# RL6678_IP_SVD register map
Vendor: Realtek
Registers are 32-bit, read-write, reset 0x0 unless marked. A register's access mark holds for its fields unless they carry their own. Offsets are from the block's base; [hi:lo] are bit positions; {n}, {i} and the like mark numbered series; 'fields as' and 'values as' point back to an identical list.

## DDRPHY_REG (part 2 of 2)
Base 0x41011000
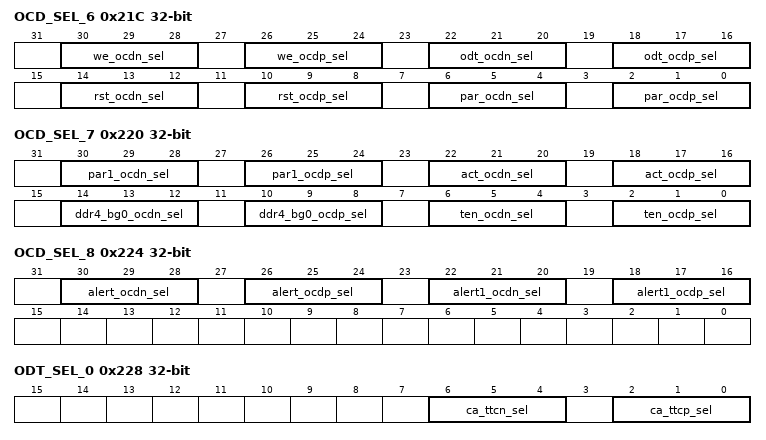
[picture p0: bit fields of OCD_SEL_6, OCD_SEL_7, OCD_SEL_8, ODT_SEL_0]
0x21C OCD_SEL_6
  [30:28] we_ocdn_sel — N-OCD selection for WEN 000: ocdn_set_0 ... 111: ocdn_set_7
  [26:24] we_ocdp_sel — P-OCD selection for WEN 000: ocdp_set_0 ... 111: ocdp_set_7
  [22:20] odt_ocdn_sel — N-OCD selection for ODT 000: ocdn_set_0 ... 111: ocdn_set_7
  [18:16] odt_ocdp_sel — P-OCD selection for ODT 000: ocdp_set_0 ... 111: ocdp_set_7
  [14:12] rst_ocdn_sel — N-OCD selection for RSTN 000: ocdn_set_0 ... 111: ocdn_set_7
  [10:8] rst_ocdp_sel — P-OCD selection for RSTN 000: ocdp_set_0 ... 111: ocdp_set_7
  [6:4] par_ocdn_sel — N-OCD selection for PAR 000: ocdn_set_0 ... 111: ocdn_set_7
  [2:0] par_ocdp_sel — P-OCD selection for PAR 000: ocdp_set_0 ... 111: ocdp_set_7
0x220 OCD_SEL_7
  [30:28] par1_ocdn_sel — N-OCD selection for PAR_1 000: ocdn_set_0 ... 111: ocdn_set_7
  [26:24] par1_ocdp_sel — P-OCD selection for PAR_1 000: ocdp_set_0 ... 111: ocdp_set_7
  [22:20] act_ocdn_sel — N-OCD selection for ACTN 000: ocdn_set_0 ... 111: ocdn_set_7
  [18:16] act_ocdp_sel — P-OCD selection for ACTN 000: ocdp_set_0 ... 111: ocdp_set_7
  [14:12] ddr4_bg0_ocdn_sel — N-OCD selection for DDR4_BG0 000: ocdn_set_0 ... 111: ocdn_set_7
  [10:8] ddr4_bg0_ocdp_sel — P-OCD selection for DDR4_BG0 000: ocdp_set_0 ... 111: ocdp_set_7
  [6:4] ten_ocdn_sel — N-OCD selection for DDR4_TEN 000: ocdn_set_0 ... 111: ocdn_set_7
  [2:0] ten_ocdp_sel — P-OCD selection for DDR4_TEN 000: ocdp_set_0 ... 111: ocdp_set_7
0x224 OCD_SEL_8
  [30:28] alert_ocdn_sel — N-OCD selection for ALERT 000: ocdn_set_0 ... 111: ocdn_set_7
  [26:24] alert_ocdp_sel — P-OCD selection for ALERT 000: ocdp_set_0 ... 111: ocdp_set_7
  [22:20] alert1_ocdn_sel — N-OCD selection for ALERT_1 000: ocdn_set_0 ... 111: ocdn_set_7
  [18:16] alert1_ocdp_sel — P-OCD selection for ALERT_1 000: ocdp_set_0 ... 111: ocdp_set_7
0x228 ODT_SEL_0
  [6:4] ca_ttcn_sel — TTCN selection for all address/command pad, except CKE and CSN 000: odt_ttcn_set_0 ... 111: odt_ttcn_set_7
  [2:0] ca_ttcp_sel — TTCP selection for all address/command pad, except CKE and CSN 000: odt_ttcp_set_0 ... 111: odt_ttcp_set_7
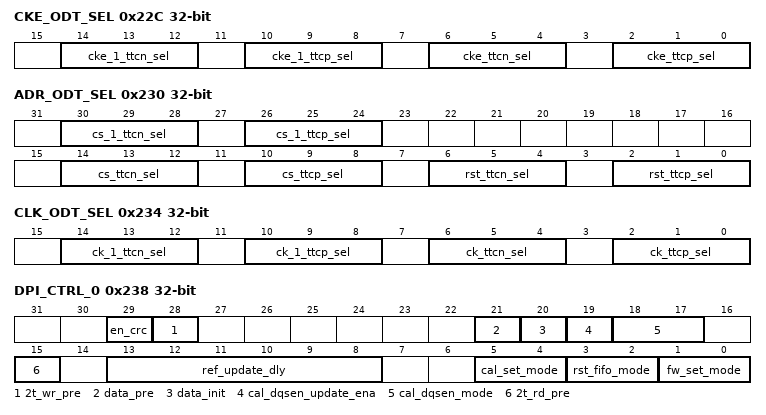
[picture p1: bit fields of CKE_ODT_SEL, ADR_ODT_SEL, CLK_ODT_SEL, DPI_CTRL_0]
0x22C CKE_ODT_SEL
  [14:12] cke_1_ttcn_sel — TTCN selection for CKE_1 (no use) 000: odt_ttcn_set_0 ... 111: odt_ttcn_set_7
  [10:8] cke_1_ttcp_sel — TTCP selection for CKE_1 (no use) 000: odt_ttcp_set_0 ... 111: odt_ttcp_set_7
  [6:4] cke_ttcn_sel — TTCN selection for CKE 000: odt_ttcn_set_0 ... 111: odt_ttcn_set_7
  [2:0] cke_ttcp_sel — TTCP selection for CKE 000: odt_ttcp_set_0 ... 111: odt_ttcp_set_7
0x230 ADR_ODT_SEL
  [30:28] cs_1_ttcn_sel — TTCN selection for CS_1 000: odt_ttcn_set_0 ... 111: odt_ttcn_set_7
  [26:24] cs_1_ttcp_sel — TTCP selection for CS_1 000: odt_ttcp_set_0 ... 111: odt_ttcp_set_7
  [14:12] cs_ttcn_sel — TTCN selection for CS 000: odt_ttcn_set_0 ... 111: odt_ttcn_set_7
  [10:8] cs_ttcp_sel — TTCP selection for CS 000: odt_ttcp_set_0 ... 111: odt_ttcp_set_7
  [6:4] rst_ttcn_sel — TTCN selection for RSTN 000: odt_ttcn_set_0 ... 111: odt_ttcn_set_7
  [2:0] rst_ttcp_sel — TTCP selection for RSTN 000: odt_ttcp_set_0 ... 111: odt_ttcp_set_7
0x234 CLK_ODT_SEL
  [14:12] ck_1_ttcn_sel — TTCN selection for CLK_1 000: odt_ttcn_set_0 ... 111: odt_ttcn_set_7
  [10:8] ck_1_ttcp_sel — TTCP selection for CLK_1 000: odt_ttcp_set_0 ... 111: odt_ttcp_set_7
  [6:4] ck_ttcn_sel — TTCN selection for CLK 000: odt_ttcn_set_0 ... 111: odt_ttcn_set_7
  [2:0] ck_ttcp_sel — TTCP selection for CLK 000: odt_ttcp_set_0 ... 111: odt_ttcp_set_7
0x238 DPI_CTRL_0
  [29] en_crc — [1] CRC enable (post one T more) for DDR4 only [0] no CRC
  [28] 2t_wr_pre — [1] 2T preamble for DDR4 only(Write) [0] 1T preamble
  [21] data_pre — 1: Enable Tx DQ preamble, enable this function will add 2T write delay in 2to1 mode, or 1T write delay in 1to1 mode
  [20] data_init — Set the Tx initial value of DQ/DM
  [19] cal_dqsen_update_ena — Enable HW auto-update tm_dqsen_ftun calibration value
  [18:17] cal_dqsen_mode — tm_dqs_en calibration set mode [00] during no read operation [01] during refresh [10] [11] disable auto calibration
  [15] 2t_rd_pre — [1] 2T preamble for DDR4 only (READ) [0] 1T preamble
  [13:8] ref_update_dly — Update delay chain setting after receiving refresh command
  [5:4] cal_set_mode — 3-point calibration set mode [00] during no read operation [01] during refresh [10] immediately [11] disable auto calibration
  [3:2] rst_fifo_mode — Reset read FIFO pointer mode [00] during no read operation [01] during refresh [10] disable reset FIFO pointer [11] force reset FIFO pointer
  [1:0] fw_set_mode — FW set delay chain of data slice mode [00] READ:during no read; WRITE: during refresh [01] during refresh [10] immediately [11] reserved
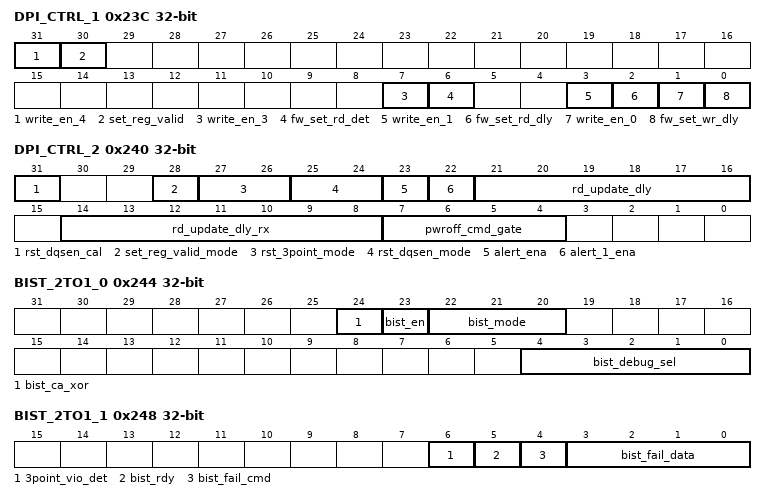
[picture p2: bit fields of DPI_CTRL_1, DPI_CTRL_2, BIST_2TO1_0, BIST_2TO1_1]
0x23C DPI_CTRL_1 access per field
  [31] write_en_4 wo — Enable of the following row
  [30] set_reg_valid rw — Set dll/rw register flow is as 1st: set_reg_valid = 0 2nd: ser any other dll/rw register 3rd : set_reg_valid = 1
  [7] write_en_3 wo — Enable of the following row
  [6] fw_set_rd_det wo — FW set read delay chain of valid window detection (one cycle pulse, HW auto clear)
  [3] write_en_1 wo — Enable of the following row
  [2] fw_set_rd_dly wo — FW set read delay chain TE and Delta of data slice (one cycle pulse, HW auto clear)
  [1] write_en_0 wo — Enable of the following row
  [0] fw_set_wr_dly rw — FW set write delay chain of data slice (one cycle pulse, HW auto clear)
0x240 DPI_CTRL_2
  [31] rst_dqsen_cal — 1'b0: disable reset fw_tm_dqs_en_ftun when reset dqsen_gen 1'b1: enable reset fw_tm_dqs_en_ftun when reset dqsen_gen
  [28] set_reg_valid_mode — [0] trigger set_reg_valid manually [1] trigger set_reg_valid automatically
  [27:26] rst_3point_mode — Reset dqsen_gen mode [00] disable reset 3 point [01] force reset 3 point [10] reserved [11] during refresh
  [25:24] rst_dqsen_mode — Reset dqsen_gen mode [00] disable reset RX dqsen_gen [01] force reset RX dqsen_gen [10] reserved [11] during refresh
  [23] alert_ena — DFI alert output enable
  [22] alert_1_ena — DFI alert_1 output enable
  [21:16] rd_update_dly — Update delay chain setting after read data enable Cmd domain 2to1 mode : > 1/2 rd_update_dly_rx +N 1to1 mode : > rd_update_dly_rx +N
  [14:8] rd_update_dly_rx — Update delay chain setting after read data enable Rx domain
  [7:4] pwroff_cmd_gate — 1: Let the following signals always be 1. [0]: let dfi_wr_cmd_01 always be 1. [1]: let dfi_wr_cmd_23 always be 1. [2]: let dfi_rd_cmd_01 always be 1. [3]: let dfi_rd_cmd_23 always be 1.
0x244 BIST_2TO1_0
  [24] bist_ca_xor — XOR dfi_wrdata_p* with dfi C/A signals for controller loopback test dfi_wrdata_xor_p0[63:0] = dfi_wrdata_p0[63:0] ^ { 8'h0, dfi_ten_in_p0, dfi_parity_in_p0, dfi_act_n_p0, dfi_bg0_p0, ^dfi_odt_p0[1:0], ^dfi_cke_1_p0[1:0], ^dfi_cke_p0[1:0], ^dfi_cs_n_1_p0[1:0], ^dfi_cs_n_p0[1:0], ^dfi_we_n_p0[1:0], ^dfi_ras_n_p0[1:0], ^dfi_cas_n_p0[1:0], dfi_bank_p0[5:0], dfi_address_ext_p0[3:0], dfi_address_p0[33:0]}; dfi_wrdata_xor_p1[63:0] = dfi_wrdata_p1[63:0] ^ { 8'h0, dfi_ten_in_p1, dfi_parity_in_p1, dfi_act_n_p1, dfi_bg0_p1, ^dfi_odt_p1[1:0], ^dfi_cke_1_p1[1:0], ^dfi_cke_p1[1:0], ^dfi_cs_n_1_p1[1:0], ^dfi_cs_n_p1[1:0], ^dfi_we_n_p1[1:0], ^dfi_ras_n_p1[1:0], ^dfi_cas_n_p1[1:0], dfi_bank_p1[5:0], dfi_address_ext_p1[3:0], dfi_address_p1[33:0]};
  [23] bist_en — 1Enable bist circuit in PHY. 0Disable bist circuit & reset all flag of bist.
  [22:20] bist_mode — Bist mode: 000 PRBS11. 001 PRBS13. 010 PRBS31.
  [4:0] bist_debug_sel — debug selection
0x248 BIST_2TO1_1 ro
  [6] 3point_vio_det — 1 means Rx 3-point lead/lag has happened. To clear this flag, set VALID_WIN_DET_PFIFO_*, VALID_WIN_DET_NFIFO_* to all 0.
  [5] bist_rdy — When bist is finished, then bist_rdy = 1 until bist_en = 0.
  [4] bist_fail_cmd — Reserved.
  [3:0] bist_fail_data — Fail flag for DDR PHY's data slice. If bist fail, then fail flag = 1 until bist_en = 0.
0x24C BIST_PT
  [31:0] bist_pattern — BIST initial pattern
0x250 BIST_DEBUG ro
  [31:0] bist_debug — BIST debug out
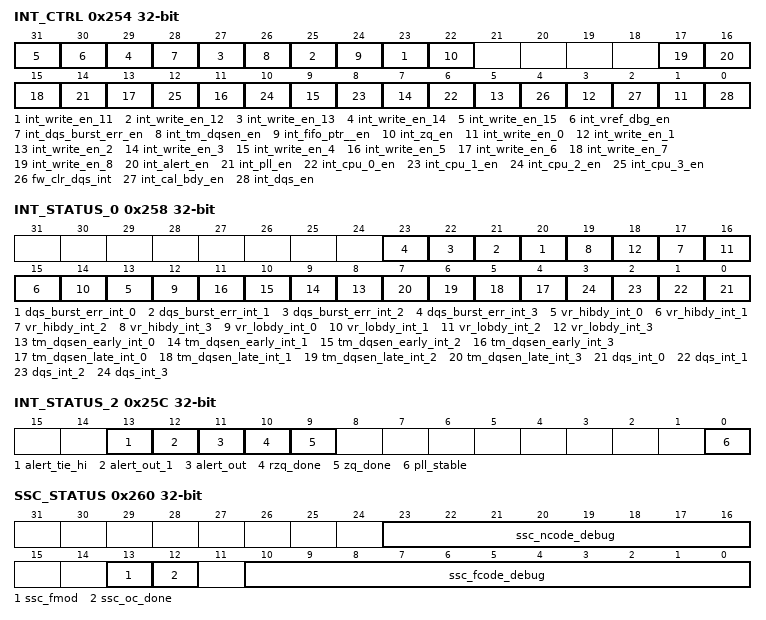
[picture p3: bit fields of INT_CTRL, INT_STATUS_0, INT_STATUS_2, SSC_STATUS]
0x254 INT_CTRL access per field
  [2n+1] int_write_en_{n} wo (n=11..15) — Enable of the following row
  [30] int_vref_dbg_en wo — Vref debug INT enable
  [28] int_dqs_burst_err_en rw — Rx DQS burst length error INT enable
  [26] int_tm_dqsen_en rw — tm_dqs_en calibration INT enable
  [24] int_fifo_ptr__en rw — fifo_prt_int enable
  [22] int_zq_en rw — Enable ZQ / RZQ done interrupt
  [2n+1] int_write_en_{n} wo (n=0..8) — Enable of the following row
  [16] int_alert_en rw — Enable alert_out interrupt
  [14] int_pll_en rw — Enable PLL stable interrupt
  [2n+6] int_cpu_{n}_en rw (n=0..3) — To CPU {n} interrupt enable
  [4] fw_clr_dqs_int wo — FW clear dqs_int & tm_dqsen_late_int & tm_dqsen_early_int (one cycle pulse, HW auto clear)
  [2] int_cal_bdy_en rw — cal_bdy_int enable
  [0] int_dqs_en rw — dqs_int enable
0x258 INT_STATUS_0
  [n+20] dqs_burst_err_int_{n} (n=0..3) — dqs_burst_err_int of data slice{n}
  [2n+13] vr_hibdy_int_{n} (n=0..3) — Byte-{n} Vref hit high boundary
  [2n+12] vr_lobdy_int_{n} (n=0..3) — Byte-{n} Vref hit low boundary
  [n+8] tm_dqsen_early_int_{n} (n=0..3) — tm_dqs_en calibration early int of slice {n}
  [n+4] tm_dqsen_late_int_{n} (n=0..3) — tm_dqs_en calibration late int of slice {n}
  [n] dqs_int_{n} (n=0..3) — dqs_int of data slice{n}
0x25C INT_STATUS_2
  [13] alert_tie_hi — 1'b1 means alert pad was tied to high
  [12] alert_out_1 — 1'b1 means alert_out_1 goes low
  [11] alert_out — 1'b1 means alert_out_0 goes low
  [10] rzq_done — RZQ calibration done
  [9] zq_done — ZQ calibration done
  [0] pll_stable
0x260 SSC_STATUS ro
  [23:16] ssc_ncode_debug — Ncode of PLL using now, for debug
  [13] ssc_fmod — 1 : under-clock 0 : over-clock
  [12] ssc_oc_done — Indicate over-clock or under-clock done
  [10:0] ssc_fcode_debug — Fcode of PLL using now, for debug
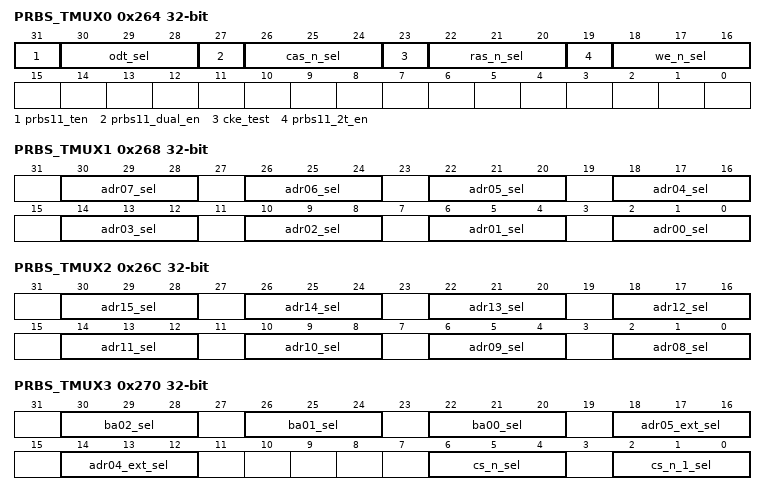
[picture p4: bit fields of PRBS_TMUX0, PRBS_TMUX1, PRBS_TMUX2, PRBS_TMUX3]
0x264 PRBS_TMUX0
  [31] prbs11_ten — PRBS11 test enable
  [30:28] odt_sel — 000: force 0 001: force 1 010: PRBS11 011: PRBS11 invert 100: PRBS11 delay one clock cycle 101: from test_pattern register 110: test_pattern invert
  [27] prbs11_dual_en — PRBS11 Dual edge enable
  [26:24] cas_n_sel — 000: force 0 001: force 1 010: PRBS11 011: PRBS11 invert 100: PRBS11 delay one clock cycle 101: from test_pattern register 110: test_pattern invert
  [23] cke_test — 1: force 1 ,0: force 0
  [22:20] ras_n_sel — 000: force 0 001: force 1 010: PRBS11 011: PRBS11 invert 100: PRBS11 delay one clock cycle 101: from test_pattern register 110: test_pattern invert
  [19] prbs11_2t_en — 1: CMD 2T ,0: CMD 1T
  [18:16] we_n_sel — 000: force 0 001: force 1 010: PRBS11 011: PRBS11 invert 100: PRBS11 delay one clock cycle 101: from test_pattern register 110: test_pattern invert
0x268 PRBS_TMUX1
  [4n+2:4n] adr{n:02}_sel (n=0..7) — 000: force 0 001: force 1 010: PRBS11 011: PRBS11 invert 100: PRBS11 delay one clock cycle 101: from test_pattern register 110: test_pattern invert
0x26C PRBS_TMUX2
  [4n-30:4n-32] adr{n:02}_sel (n=8..15) — 000: force 0 001: force 1 010: PRBS11 011: PRBS11 invert 100: PRBS11 delay one clock cycle 101: from test_pattern register 110: test_pattern invert
0x270 PRBS_TMUX3
  [30:28] ba02_sel — 000: force 0 001: force 1 010: PRBS11 011: PRBS11 invert 100: PRBS11 delay one clock cycle 101: from test_pattern register 110: test_pattern invert
  [26:24] ba01_sel — 000: force 0 001: force 1 010: PRBS11 011: PRBS11 invert 100: PRBS11 delay one clock cycle 101: from test_pattern register 110: test_pattern invert
  [22:20] ba00_sel — 000: force 0 001: force 1 010: PRBS11 011: PRBS11 invert 100: PRBS11 delay one clock cycle 101: from test_pattern register 110: test_pattern invert
  [18:16] adr05_ext_sel — 000: force 0 001: force 1 010: PRBS11 011: PRBS11 invert 100: PRBS11 delay one clock cycle 101: from test_pattern register 110: test_pattern invert
  [14:12] adr04_ext_sel — 000: force 0 001: force 1 010: PRBS11 011: PRBS11 invert 100: PRBS11 delay one clock cycle 101: from test_pattern register 110: test_pattern invert
  [6:4] cs_n_sel — 000: force 0 001: force 1 010: PRBS11 011: PRBS11 invert 100: PRBS11 delay one clock cycle 101: from test_pattern register 110: test_pattern invert
  [2:0] cs_n_1_sel — 000: force 0 001: force 1 010: PRBS11 011: PRBS11 invert 100: PRBS11 delay one clock cycle 101: from test_pattern register 110: test_pattern invert
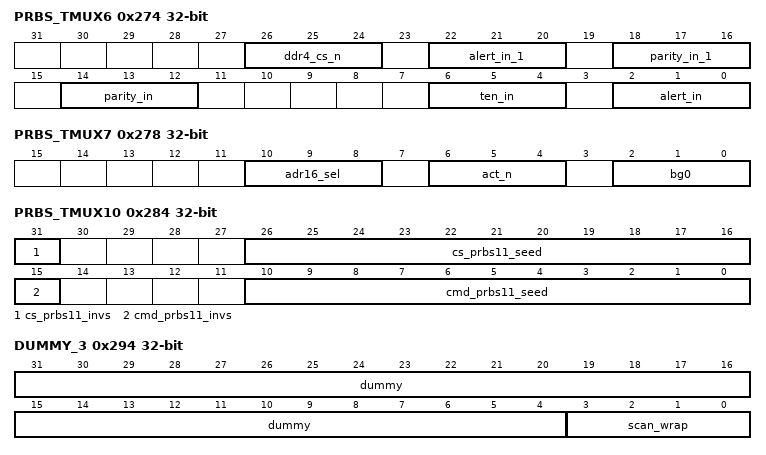
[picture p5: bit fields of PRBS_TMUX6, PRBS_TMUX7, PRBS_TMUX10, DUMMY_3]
0x274 PRBS_TMUX6
  [26:24] ddr4_cs_n — 000: force 0 001: force 1 010: PRBS11 011: PRBS11 invert 100: PRBS11 delay one clock cycle 101: from test_pattern register 110: test_pattern invert
  [22:20] alert_in_1 — 000: force 0 001: force 1 010: PRBS11 011: PRBS11 invert 100: PRBS11 delay one clock cycle 101: from test_pattern register 110: test_pattern invert
  [18:16] parity_in_1 — 000: force 0 001: force 1 010: PRBS11 011: PRBS11 invert 100: PRBS11 delay one clock cycle 101: from test_pattern register 110: test_pattern invert
  [14:12] parity_in — 000: force 0 001: force 1 010: PRBS11 011: PRBS11 invert 100: PRBS11 delay one clock cycle 101: from test_pattern register 110: test_pattern invert
  [6:4] ten_in — 000: force 0 001: force 1 010: PRBS11 011: PRBS11 invert 100: PRBS11 delay one clock cycle 101: from test_pattern register 110: test_pattern invert
  [2:0] alert_in — 000: force 0 001: force 1 010: PRBS11 011: PRBS11 invert 100: PRBS11 delay one clock cycle 101: from test_pattern register 110: test_pattern invert
0x278 PRBS_TMUX7
  [10:8] adr16_sel — 000: force 0 001: force 1 010: PRBS11 011: PRBS11 invert 100: PRBS11 delay one clock cycle 101: from test_pattern register 110: test_pattern invert
  [6:4] act_n — 000: force 0 001: force 1 010: PRBS11 011: PRBS11 invert 100: PRBS11 delay one clock cycle 101: from test_pattern register 110: test_pattern invert
  [2:0] bg0 — 000: force 0 001: force 1 010: PRBS11 011: PRBS11 invert 100: PRBS11 delay one clock cycle 101: from test_pattern register 110: test_pattern invert
0x27C PRBS_TMUX8
  [31:0] test_pattern — 32-bit test pattern for prbs11 or ten: [16: 0] : Addr[16:0] [18:17] : Ext_Addr[5:4] [21:19] : BA [22] : CS_n [23] : CS_n_1 [24] : RESET_n [25] : CKE [26] : ODT [27] : WE_n [28] : CAS_n [29] : RAS_n [30] : CKE_1
0x280 PRBS_TMUX9
  [31:0] test4_pattern — 32-bit test pattern for prbs11 or ten: [31:8] : reserved [07] : DDR4_CS_n [06] : ACT_n [05] : DDR4_CKE [04] : DDR4_BG0 [03] : PARITY_in [02] : PARITY_in_1 [01] : ALERT_in [00] : ALERT_in_1
0x284 PRBS_TMUX10
  [31] cs_prbs11_invs — inverted PRBS11 for CS
  [26:16] cs_prbs11_seed — PRBS11 seed for CS
  [15] cmd_prbs11_invs — inverted PRBS11 for CMD/ADR
  [10:0] cmd_prbs11_seed — PRBS11 seed for CMD / ADR
{0x288+4i} DUMMY_{i} (i=0..2)
  [31:0] dummy
0x294 DUMMY_3
  [31:4] dummy
  [3:0] scan_wrap — dummy register for scan test coverage
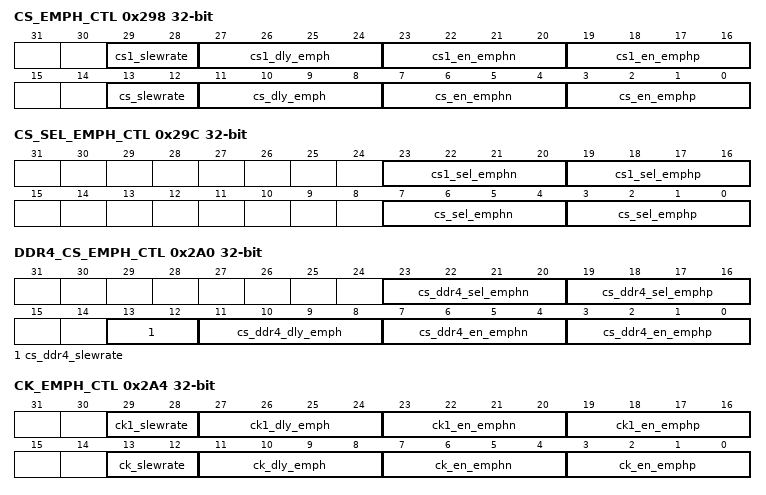
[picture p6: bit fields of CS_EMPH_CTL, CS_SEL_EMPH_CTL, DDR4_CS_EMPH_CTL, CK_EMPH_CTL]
0x298 CS_EMPH_CTL
  [29:28] cs1_slewrate — CS1_n slew rate control pin
  [27:24] cs1_dly_emph — CS1_n Delay tap control pin (no use)
  [23:20] cs1_en_emphn — CS1_n Emphasis control pin (no use)
  [19:16] cs1_en_emphp — CS1_n Emphasis control pin (no use)
  [13:12] cs_slewrate — CS_n slew rate control pin
  [11:8] cs_dly_emph — CS_n Delay tap control pin (no use)
  [7:4] cs_en_emphn — CS_n Emphasis control pin (no use)
  [3:0] cs_en_emphp — CS_n Emphasis control pin (no use)
0x29C CS_SEL_EMPH_CTL
  [23:20] cs1_sel_emphn — CS1_n SEL Emphasis control pin
  [19:16] cs1_sel_emphp — CS1_n SEL Emphasis control pin
  [7:4] cs_sel_emphn — CS_n SEL Emphasis control pin
  [3:0] cs_sel_emphp — CS_n SEL Emphasis control pin
0x2A0 DDR4_CS_EMPH_CTL
  [23:20] cs_ddr4_sel_emphn — CS_n SEL Emphasis control pin
  [19:16] cs_ddr4_sel_emphp — CS_n SEL Emphasis control pin
  [13:12] cs_ddr4_slewrate — DDR4 CS_n slew rate control pin
  [11:8] cs_ddr4_dly_emph — DDR4 CS_n Delay tap control pin (no use)
  [7:4] cs_ddr4_en_emphn — DDR4 CS_n Emphasis control pin (no use)
  [3:0] cs_ddr4_en_emphp — DDR4 CS_n Emphasis control pin (no use)
0x2A4 CK_EMPH_CTL
  [29:28] ck1_slewrate — CK1 slew rate control pin
  [27:24] ck1_dly_emph — CK1 Delay tap control pin (no use)
  [23:20] ck1_en_emphn — CK1 Emphasis control pin (no use)
  [19:16] ck1_en_emphp — CK1 Emphasis control pin (no use)
  [13:12] ck_slewrate — CK slew rate control pin
  [11:8] ck_dly_emph — CK Delay tap control pin (no use)
  [7:4] ck_en_emphn — CK Emphasis control pin (no use)
  [3:0] ck_en_emphp — CK Emphasis control pin (no use)
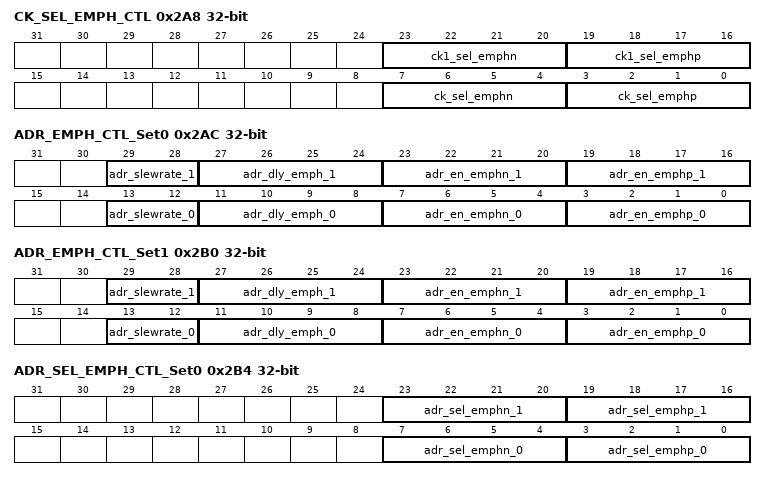
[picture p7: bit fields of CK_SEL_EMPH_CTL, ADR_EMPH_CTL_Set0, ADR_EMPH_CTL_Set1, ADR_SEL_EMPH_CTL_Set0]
0x2A8 CK_SEL_EMPH_CTL
  [23:20] ck1_sel_emphn — CK1 SEL Emphasis control pin
  [19:16] ck1_sel_emphp — CK1 SEL Emphasis control pin
  [7:4] ck_sel_emphn — CK sel Emphasis control pin
  [3:0] ck_sel_emphp — CK sel Emphasis control pin
0x2AC ADR_EMPH_CTL_Set0
  [29:28] adr_slewrate_1 — ADR/CMD slew rate control pin
  [27:24] adr_dly_emph_1 — ADR/CMD Delay tap control pin 1 (no use)
  [23:20] adr_en_emphn_1 — ADR/CMD Emphasis control pin 1 (no use)
  [19:16] adr_en_emphp_1 — ADR/CMD Emphasis control pin 1 (no use)
  [13:12] adr_slewrate_0 — ADR/CMD slew rate control pin 0
  [11:8] adr_dly_emph_0 — ADR/CMD Delay tap control pin 0 (no use)
  [7:4] adr_en_emphn_0 — ADR/CMD Emphasis control pin 0 (no use)
  [3:0] adr_en_emphp_0 — ADR/CMD Emphasis control pin 0 (no use)
0x2B0 ADR_EMPH_CTL_Set1
  fields as ADR_EMPH_CTL_Set0
0x2B4 ADR_SEL_EMPH_CTL_Set0
  [23:20] adr_sel_emphn_1 — ADR/CMD Emphasis control pin 1
  [19:16] adr_sel_emphp_1 — ADR/CMD Emphasis control pin 1
  [7:4] adr_sel_emphn_0 — ADR/CMD Emphasis control pin 0
  [3:0] adr_sel_emphp_0 — ADR/CMD Emphasis control pin 0
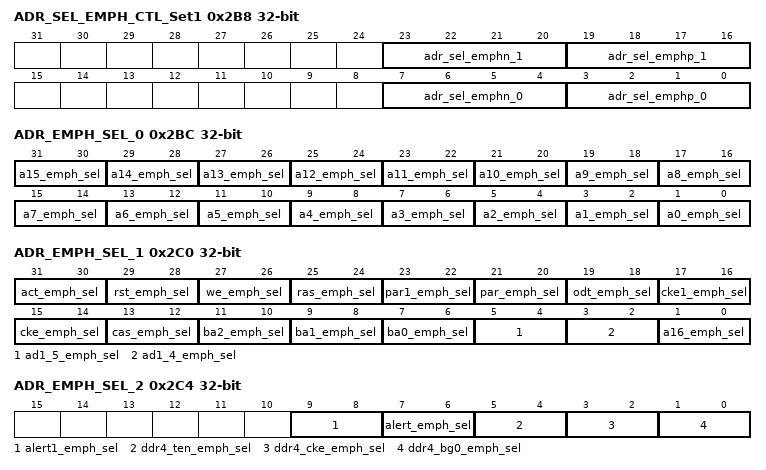
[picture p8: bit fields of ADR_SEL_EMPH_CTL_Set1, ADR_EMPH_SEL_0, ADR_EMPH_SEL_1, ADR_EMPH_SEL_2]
0x2B8 ADR_SEL_EMPH_CTL_Set1
  fields as ADR_SEL_EMPH_CTL_Set0
0x2BC ADR_EMPH_SEL_0
  [2n+1:2n] a{n}_emph_sel (n=0..15) — Tx emphasis control of PAD_DDR_A{n} 00: use ADR/CMD emphasis control set 0 01: use ADR/CMD emphasis control set 1 10: use ADR/CMD emphasis control set 2 11: use ADR/CMD emphasis control set 3
0x2C0 ADR_EMPH_SEL_1
  [31:30] act_emph_sel — Tx emphasis control of PAD_DDR_ACTN 00: use ADR/CMD emphasis control set 0 01: use ADR/CMD emphasis control set 1 10: use ADR/CMD emphasis control set 2 11: use ADR/CMD emphasis control set 3
  [29:28] rst_emph_sel — Tx emphasis control of PAD_DDR_RSTN 00: use ADR/CMD emphasis control set 0 01: use ADR/CMD emphasis control set 1 10: use ADR/CMD emphasis control set 2 11: use ADR/CMD emphasis control set 3
  [27:26] we_emph_sel — Tx emphasis control of PAD_DDR_WEN 00: use ADR/CMD emphasis control set 0 01: use ADR/CMD emphasis control set 1 10: use ADR/CMD emphasis control set 2 11: use ADR/CMD emphasis control set 3
  [25:24] ras_emph_sel — Tx emphasis control of PAD_DDR_RASN 00: use ADR/CMD emphasis control set 0 01: use ADR/CMD emphasis control set 1 10: use ADR/CMD emphasis control set 2 11: use ADR/CMD emphasis control set 3
  [23:22] par1_emph_sel — Tx emphasis control of PAD_DDR4_PAR_1 00: use ADR/CMD emphasis control set 0 01: use ADR/CMD emphasis control set 1 10: use ADR/CMD emphasis control set 2 11: use ADR/CMD emphasis control set 3
  [21:20] par_emph_sel — Tx emphasis control of PAD_DDR4_PAR 00: use ADR/CMD emphasis control set 0 01: use ADR/CMD emphasis control set 1 10: use ADR/CMD emphasis control set 2 11: use ADR/CMD emphasis control set 3
  [19:18] odt_emph_sel — Tx emphasis control of PAD_DDR_ODT 00: use ADR/CMD emphasis control set 0 01: use ADR/CMD emphasis control set 1 10: use ADR/CMD emphasis control set 2 11: use ADR/CMD emphasis control set 3
  [17:16] cke1_emph_sel — Tx emphasis control of PAD_DDR_CKE_1 00: use ADR/CMD emphasis control set 0 01: use ADR/CMD emphasis control set 1 10: use ADR/CMD emphasis control set 2 11: use ADR/CMD emphasis control set 3
  [15:14] cke_emph_sel — Tx emphasis control of PAD_DDR_CKE 00: use ADR/CMD emphasis control set 0 01: use ADR/CMD emphasis control set 1 10: use ADR/CMD emphasis control set 2 11: use ADR/CMD emphasis control set 3
  [13:12] cas_emph_sel — Tx emphasis control of PAD_DDR_CASN 00: use ADR/CMD emphasis control set 0 01: use ADR/CMD emphasis control set 1 10: use ADR/CMD emphasis control set 2 11: use ADR/CMD emphasis control set 3
  [11:10] ba2_emph_sel — Tx emphasis control of PAD_DDR_BA2 00: use ADR/CMD emphasis control set 0 01: use ADR/CMD emphasis control set 1 10: use ADR/CMD emphasis control set 2 11: use ADR/CMD emphasis control set 3
  [9:8] ba1_emph_sel — Tx emphasis control of PAD_DDR_BA1 00: use ADR/CMD emphasis control set 0 01: use ADR/CMD emphasis control set 1 10: use ADR/CMD emphasis control set 2 11: use ADR/CMD emphasis control set 3
  [7:6] ba0_emph_sel — Tx emphasis control of PAD_DDR_BA0 00: use ADR/CMD emphasis control set 0 01: use ADR/CMD emphasis control set 1 10: use ADR/CMD emphasis control set 2 11: use ADR/CMD emphasis control set 3
  [5:4] ad1_5_emph_sel — Tx emphasis control of PAD_DDR_AD1_5 00: use ADR/CMD emphasis control set 0 01: use ADR/CMD emphasis control set 1 10: use ADR/CMD emphasis control set 2 11: use ADR/CMD emphasis control set 3
  [3:2] ad1_4_emph_sel — Tx emphasis control of PAD_DDR_AD1_4 00: use ADR/CMD emphasis control set 0 01: use ADR/CMD emphasis control set 1 10: use ADR/CMD emphasis control set 2 11: use ADR/CMD emphasis control set 3
  [1:0] a16_emph_sel — Tx emphasis control of PAD_DDR_A16 00: use ADR/CMD emphasis control set 0 01: use ADR/CMD emphasis control set 1 10: use ADR/CMD emphasis control set 2 11: use ADR/CMD emphasis control set 3
0x2C4 ADR_EMPH_SEL_2
  [9:8] alert1_emph_sel — Tx emphasis control of PAD_DDR_ALERT_1 00: use ADR/CMD emphasis control set 0 01: use ADR/CMD emphasis control set 1 10: use ADR/CMD emphasis control set 2 11: use ADR/CMD emphasis control set 3
  [7:6] alert_emph_sel — Tx emphasis control of PAD_DDR_ALERT 00: use ADR/CMD emphasis control set 0 01: use ADR/CMD emphasis control set 1 10: use ADR/CMD emphasis control set 2 11: use ADR/CMD emphasis control set 3
  [5:4] ddr4_ten_emph_sel — Tx emphasis control of PAD_DDR4_TEN 00: use ADR/CMD emphasis control set 0 01: use ADR/CMD emphasis control set 1 10: use ADR/CMD emphasis control set 2 11: use ADR/CMD emphasis control set 3
  [3:2] ddr4_cke_emph_sel — Tx emphasis control of PAD_DDR4_CKE 00: use ADR/CMD emphasis control set 0 01: use ADR/CMD emphasis control set 1 10: use ADR/CMD emphasis control set 2 11: use ADR/CMD emphasis control set 3
  [1:0] ddr4_bg0_emph_sel — Tx emphasis control of PAD_DDR4_BG0 00: use ADR/CMD emphasis control set 0 01: use ADR/CMD emphasis control set 1 10: use ADR/CMD emphasis control set 2 11: use ADR/CMD emphasis control set 3
0x2C8 DBG_READ_0 ro
  [31:0] dqsen_dbg — Use dqsen_dbg_sel[1:0] to select dqsen_dbg_0, dqsen_dbg_1, dqsen_dbg_2, dqsen_dbg_3
0x2CC DBG_READ_1 ro
  [31:0] dpi_dbg_dll — Use dpi_dbg_dll_sel to select dpi_debug_dll[31:0] or dpi_debug_dll[63:32]
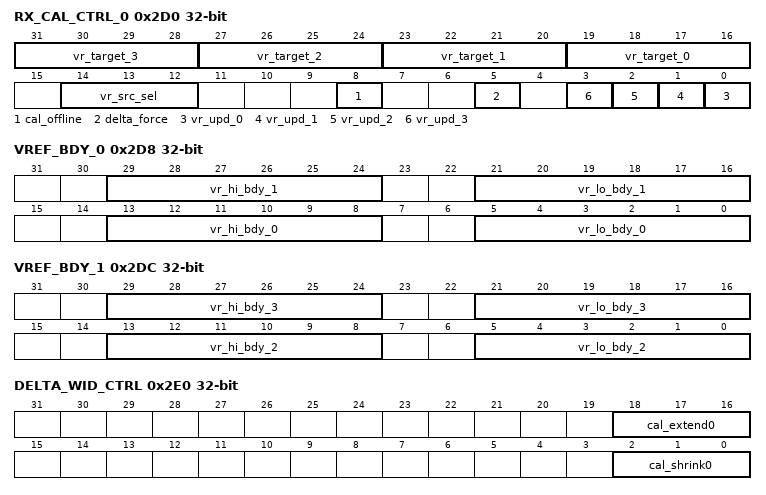
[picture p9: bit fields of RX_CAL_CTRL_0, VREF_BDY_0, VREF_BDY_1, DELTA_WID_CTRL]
0x2D0 RX_CAL_CTRL_0
  [4n+19:4n+16] vr_target_{n} (n=0..3) — Vref calibration process will stop if the minimum delta width is greater than or equal to this value. This is for byte-{n} Vref.
  [14:12] vr_src_sel — Select data source of Vref update criteria
  [8] cal_offline — 1: TE only move in one direction, and Delta only decrease. This mode should only be used in offline or fore-ground calibration to find the minimum working Rx delay taps.
  [5] delta_force — force delta value without double-buffer
  [n] vr_upd_{n} (n=0..3) — 1: vref_s_{n} can be applied to Vref pad by fw_set_rd_dly
0x2D4 RX_CAL_CTRL_1
  [5:0] vr_cnt_target — update Vref when target count is reached 0 : disable Vref calibration
0x2D8 VREF_BDY_0
  [29:24] vr_hi_bdy_1 — Vref1 high boundary for rw_blk_01
  [21:16] vr_lo_bdy_1 — Vref1 low boundary for rw_blk_01
  [13:8] vr_hi_bdy_0 — Vref0 high boundary for rw_blk_01
  [5:0] vr_lo_bdy_0 — Vref0 low boundary for rw_blk_01
0x2DC VREF_BDY_1
  [29:24] vr_hi_bdy_3 — Vref3 high boundary for rw_blk_23
  [21:16] vr_lo_bdy_3 — Vref3 low boundary for rw_blk_23
  [13:8] vr_hi_bdy_2 — Vref2 high boundary for rw_blk_23
  [5:0] vr_lo_bdy_2 — Vref2 low boundary for rw_blk_23
0x2E0 DELTA_WID_CTRL
  [18:16] cal_extend0 — extend width of delta when calibration result is extend[0] = 1 [2's complement format] (sign, 2.0) 000: 0 001: 1 010: 2 011: 3
  [2:0] cal_shrink0 — shrink width of delta when calibration result is shrink[0] = 1 [2's complement format] (sign, 2.0) 111: -1 110: -2 101: -3 100: -4
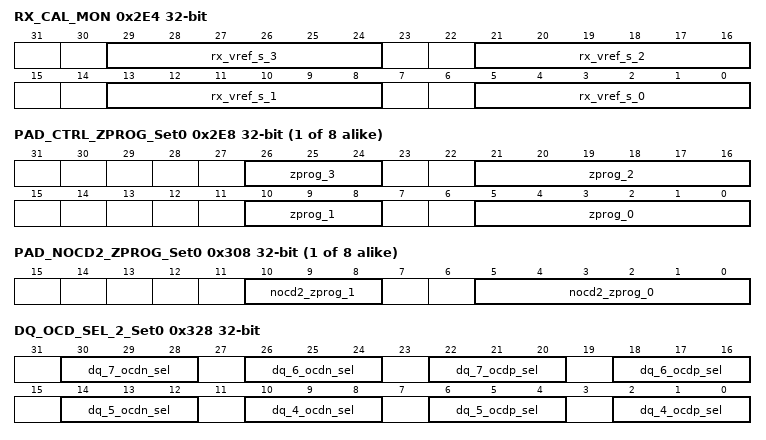
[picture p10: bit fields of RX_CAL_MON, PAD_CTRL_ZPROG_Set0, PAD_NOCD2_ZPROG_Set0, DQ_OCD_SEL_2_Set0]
0x2E4 RX_CAL_MON ro
  [8n+5:8n] rx_vref_s_{n} (n=0..3) — calibrated Vref value of byte-{n}
{0x2E8+4i} PAD_CTRL_ZPROG_Set{i} (i=0..7)
  [26:24] zprog_3 — NODT vpcal_sel
  [21:16] zprog_2 — NODT pad pocd value
  [10:8] zprog_1 — NOCD vpcal_sel
  [5:0] zprog_0 — NOCD pad pocd value
{0x308+4i} PAD_NOCD2_ZPROG_Set{i} (i=0..7)
  [10:8] nocd2_zprog_1 — NOCD2 vpcal_sel
  [5:0] nocd2_zprog_0 — NOCD2 pad pocd value
0x328 DQ_OCD_SEL_2_Set0
  [30:28] dq_7_ocdn_sel — Set 0: NT2 selection for slice3 DQ Set 1: EN_EMPHN selection for slice3 DQ 000: ocdn_set_0 ... 111: ocdn_set_7
  [26:24] dq_6_ocdn_sel — Set 0: NT2 selection for slice2 DQ Set 1: EN_EMPHN selection for slice2 DQ 000: ocdn_set_0 ... 111: ocdn_set_7
  [22:20] dq_7_ocdp_sel — Set 0: PT2 selection for slice3 DQ Set 1: EN_EMPHP selection for slice3 DQ 000: ocdp_set_0 ... 111: ocdp_set_7
  [18:16] dq_6_ocdp_sel — Set 0: PT2 selection for slice2 DQ Set 1: EN_EMPHP selection for slice2 DQ 000: ocdp_set_0 ... 111: ocdp_set_7
  [14:12] dq_5_ocdn_sel — Set 0: NT2 selection for slice1 DQ Set 1: EN_EMPHN selection for slice1 DQ 000: ocdn_set_0 ... 111: ocdn_set_7
  [10:8] dq_4_ocdn_sel — Set 0: NT2 selection for slice0 DQ Set 1: EN_EMPHN selection for slice0 DQ 000: ocdn_set_0 ... 111: ocdn_set_7
  [6:4] dq_5_ocdp_sel — Set 0: PT2 selection for slice1 DQ Set 1: EN_EMPHP selection for slice1 DQ 000: ocdp_set_0 ... 111: ocdp_set_7
  [2:0] dq_4_ocdp_sel — Set 0: PT2 selection for slice0 DQ Set 1: EN_EMPHP selection for slice0 DQ 000: ocdp_set_0 ... 111: ocdp_set_7
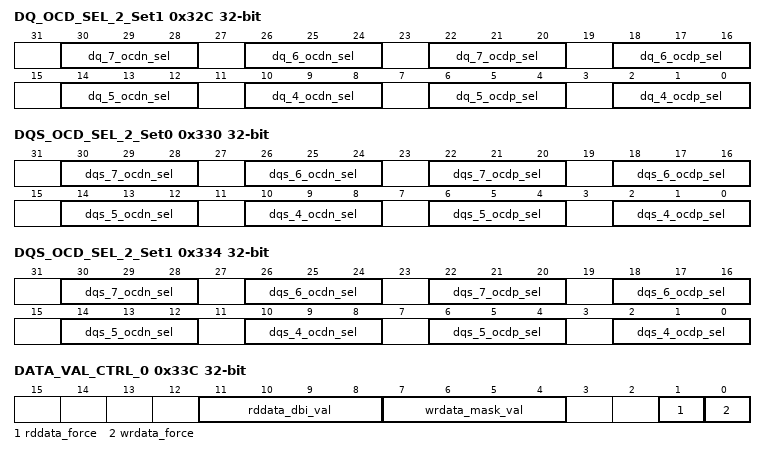
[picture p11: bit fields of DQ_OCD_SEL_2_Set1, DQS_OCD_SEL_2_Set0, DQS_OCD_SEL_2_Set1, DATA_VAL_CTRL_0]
0x32C DQ_OCD_SEL_2_Set1
  fields as DQ_OCD_SEL_2_Set0
0x330 DQS_OCD_SEL_2_Set0
  [30:28] dqs_7_ocdn_sel — Set 0: NT2 selection for DQS[3] Set 1: EN_EMPHN selection for DQS[3] 000: ocdn_set_0 ... 111: ocdn_set_7
  [26:24] dqs_6_ocdn_sel — Set 0: NT2 selection for DQS[2] Set 1: EN_EMPHN selection for DQS[2] 000: ocdn_set_0 ... 111: ocdn_set_7
  [22:20] dqs_7_ocdp_sel — Set 0: PT2 selection for DQS[3] Set 1: EN_EMPHP selection for DQS[3] 000: ocdp_set_0 ... 111: ocdp_set_7
  [18:16] dqs_6_ocdp_sel — Set 0: PT2 selection for DQS[2] Set 1: EN_EMPHP selection for DQS[2] 000: ocdp_set_0 ... 111: ocdp_set_7
  [14:12] dqs_5_ocdn_sel — Set 0: NT2 selection for DQS[1] Set 1: EN_EMPHN selection for DQS[1] 000: ocdn_set_0 ... 111: ocdn_set_7
  [10:8] dqs_4_ocdn_sel — Set 0: NT2 selection for DQS[0] Set 1: EN_EMPHN selection for DQS[0] 000: ocdn_set_0 ... 111: ocdn_set_7
  [6:4] dqs_5_ocdp_sel — Set 0: PT2 selection for DQS[1] Set 1: EN_EMPHP selection for DQS[1] 000: ocdp_set_0 ... 111: ocdp_set_7
  [2:0] dqs_4_ocdp_sel — Set 0: PT2 selection for DQS[0] Set 1: EN_EMPHP selection for DQS[0] 000: ocdp_set_0 ... 111: ocdp_set_7
0x334 DQS_OCD_SEL_2_Set1
  fields as DQS_OCD_SEL_2_Set0
0x338 DBG_READ_2 ro
  [15:0] data_en_err_type — [1:0] check result of dfi_wrdata_en_p0/p1[0] [3:2] check result of dfi_wrdata_en_p0/p1[1] [5:4] check result of dfi_wrdata_en_p0/p1[2] [7:6] check result of dfi_wrdata_en_p0/p1[3] [9:8] check result of dfi_rddata_en_p0/p1[0] [11:10] check result of dfi_rddata_en_p0/p1[1] [13:12] check result of dfi_rddata_en_p0/p1[2] [15:14] check result of dfi_rddata_en_p0/p1[3] 2'b00: No error; 2'b01: burst length cycle is odd number; 2'b10: burst length cycle is 2.
0x33C DATA_VAL_CTRL_0
  [11:8] rddata_dbi_val — Only available if rddata_force = 1. [3:0]: Control rddata_dbi value of read slice 3/2/1/0.
  [7:4] wrdata_mask_val — Only available if wrdata_force = 1. [3:0]: Control wrdata_mask value of write slice 3/2/1/0.
  [1] rddata_force — 1: Force the value of dfi_rddata_wN and dfi_rddata_dbi_wN to rddata_val and rddata_dbi_val.
  [0] wrdata_force — 1: Force the value of dfi_wrdata_pN and dfi_wrdata_mask_pN to wrdata_val and wrdata_mask_val.
0x340 DATA_VAL_CTRL_1
  [31:0] wrdata_val — Only available if wrdata_force = 1. [ 7: 0]: Control wrdata of write slice 0 [15:8]: Control wrdata of write slice 1 [23:16]: Control wrdata of write slice 2 [31:24]: Control wrdata of write slice 3
0x344 DATA_VAL_CTRL_2
  [31:0] rddata_val — Only available if rddata_force = 1. [ 7: 0]: Control rddata of read slice 0 [15:8]: Control rddata of read slice 1 [23:16]: Control rddata of read slice 2 [31:24]: Control rddata of read slice 3
0x400 RW_DMY_0
  [31:0] dummy
0x404 RW_DMY_1
  [31:0] dummy
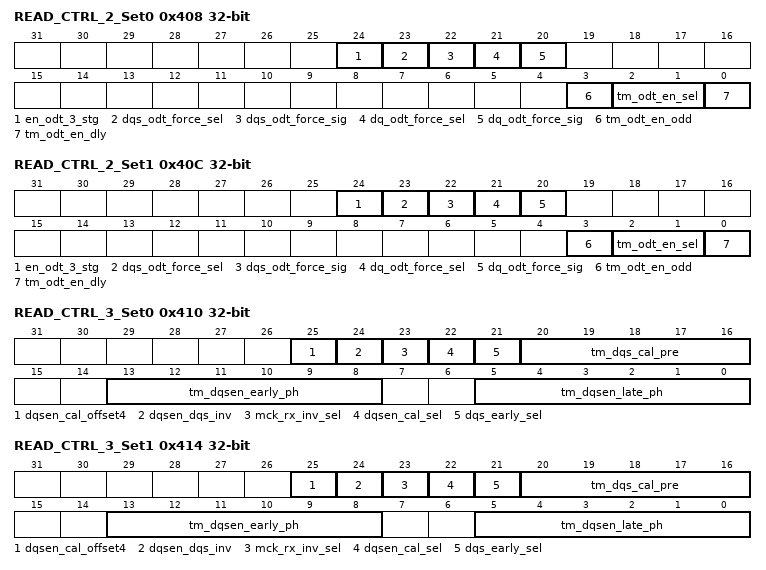
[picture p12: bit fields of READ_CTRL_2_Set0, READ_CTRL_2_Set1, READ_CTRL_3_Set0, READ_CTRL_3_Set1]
0x408 READ_CTRL_2_Set0
  [24] en_odt_3_stg — 1: turn on/off DQ/DM/DQS ODT by 3 stages. When turn on ODT, stage 1: {4'h0, ODT_value[5:4]} stage 2: {2'h0, ODT_value[5:2]} stage 3: {ODT_value[5:0]} When turn off ODT, stage 1: {ODT_value[5:0]} stage 2: {2'h0, ODT_value[5:2]} stage 3: {4'h0, ODT_value[5:4]} Enable this function will extend odt_en/IE by 2 tCK in the end. If want to enable this function, the duration of odt_en/IE should be at least 6 tCK.
  [23] dqs_odt_force_sel — DQS Rx ODT pad control. 0 : controlled by read command 1: controlled by dqs_odt_force_sig
  [22] dqs_odt_force_sig — If set dqs_odt_force_sel, DQS TE is controlled by dqs_odt_force_sig.
  [21] dq_odt_force_sel — DQ Rx ODT control. 0 : controlled by read command 1: controlled by dq_odt_force_sig
  [20] dq_odt_force_sig — If set dq_odt_force_sel, DQ TE is controlled by dq_odt_force_sig.
  [3] tm_odt_en_odd — for 2to1 mode b1 : odd length for tm_odt_en b0 : even length for tm_odt_en for 1to1 mode b1 : length add 1T
  [2:1] tm_odt_en_sel — b00: follow (odt_en + odt_en_dly) setting. b01: delay (odt_en + odt_en_dly) assert 0.5 T. b10, 2'b11: delay (odt_en + odt_en_dly) desert 0.5T.
  [0] tm_odt_en_dly — b1 : odt_en delay 1DCK
0x40C READ_CTRL_2_Set1
  fields as READ_CTRL_2_Set0
0x410 READ_CTRL_3_Set0
  [25] dqsen_cal_offset4 — 0: DQSEN Calibration offset + 2 1: DQSEN Calibration offset + 4
  [24] dqsen_dqs_inv — 0: use dqs for dqsen calibration 1: use inverted dqs for dqsen calibration (in ddr4)
  [23] mck_rx_inv_sel — 0: delay dqs_en1_set by 0.5T mck_rx 1: delay dqs_en1_set by 1T mck_rx
  [22] dqsen_cal_sel — Select dqs enable calibration algorithm.
  [21] dqs_early_sel — Select source signal of dqs early detection 0: dqs_en2 1: dqs
  [20:16] tm_dqs_cal_pre — for tm_dqs_en_ftun calibration 2to1 : tm_dqs_cal_pre = tm_dqs_en - 1
  [13:8] tm_dqsen_early_ph — tm_dqs_en calibration early delay tap
  [5:0] tm_dqsen_late_ph — tm_dqs_en calibration late delay tap
0x414 READ_CTRL_3_Set1
  fields as READ_CTRL_3_Set0
0x418 READ_CTRL_6_Set0
  [31:0] tm_odt_en — odt_en length setting 2T DCK unit for 2to1 mode 1T DCK unit for 1to1 mode
0x41C READ_CTRL_6_Set1
  fields as READ_CTRL_6_Set0
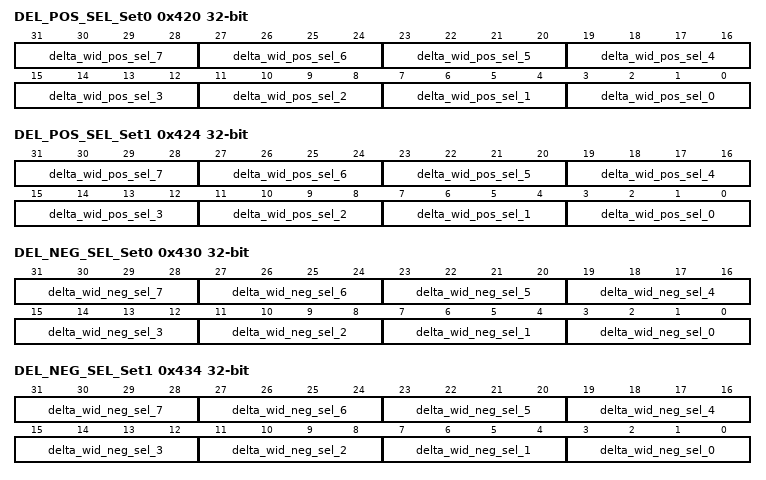
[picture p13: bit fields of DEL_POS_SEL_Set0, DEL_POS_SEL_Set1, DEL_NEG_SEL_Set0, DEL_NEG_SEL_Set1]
0x420 DEL_POS_SEL_Set0
  [4n+3:4n] delta_wid_pos_sel_{n} (n=1..7) — Left/right sampling point of positive edge 3-point calibration for dq[{n}].
  [3:0] delta_wid_pos_sel_0 — Left/right sampling point of positive edge 3-point calibration for dq[0]. 0: shift 1 taps from central point 1: shift 2 taps from central point ................ 15: shift 16 taps from central point
0x424 DEL_POS_SEL_Set1
  fields as DEL_POS_SEL_Set0
0x428 DEL_POS_SEL_DBI_Set0
  [3:0] delta_wid_pos_sel_8 — Left/right sampling point of positive edge 3-point calibration for dbi. 0: shift 1 taps from central point 1: shift 2 taps from central point ................ 15: shift 16 taps from central point
0x42C DEL_POS_SEL_DBI_Set1
  fields as DEL_POS_SEL_DBI_Set0
0x430 DEL_NEG_SEL_Set0
  [4n+3:4n] delta_wid_neg_sel_{n} (n=1..7) — Left/right sampling point of negative edge 3-point calibration for dq[{n}].
  [3:0] delta_wid_neg_sel_0 — Left/right sampling point of negative edge 3-point calibration for dq[0]. 0: shift 1 taps from central point 1: shift 2 taps from central point ................ 15: shift 16 taps from central point
0x434 DEL_NEG_SEL_Set1
  fields as DEL_NEG_SEL_Set0
0x438 DEL_NEG_SEL_DBI_Set0
  [3:0] delta_wid_neg_sel_8 — Left/right sampling point of negative edge 3-point calibration for dbi. 0: shift 1 taps from central point 1: shift 2 taps from central point ................ 15: shift 16 taps from central point
0x43C DEL_NEG_SEL_DBI_Set1
  fields as DEL_NEG_SEL_DBI_Set0
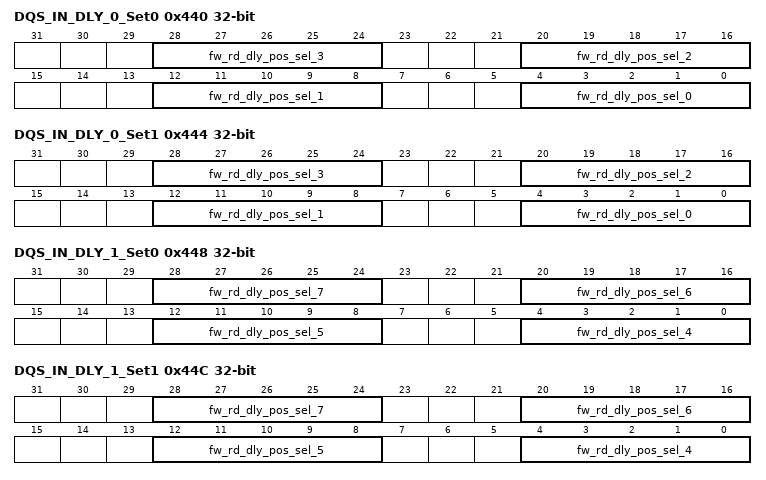
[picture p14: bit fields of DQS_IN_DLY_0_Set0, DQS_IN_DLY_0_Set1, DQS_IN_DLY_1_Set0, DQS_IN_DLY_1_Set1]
0x440 DQS_IN_DLY_0_Set0
  [8n+4:8n] fw_rd_dly_pos_sel_{n} (n=0..3) — DQS_IN[{n}] raising edge delay chain control
0x444 DQS_IN_DLY_0_Set1
  fields as DQS_IN_DLY_0_Set0
0x448 DQS_IN_DLY_1_Set0
  [8n-28:8n-32] fw_rd_dly_pos_sel_{n} (n=4..7) — DQS_IN[{n}] raising edge delay chain control
0x44C DQS_IN_DLY_1_Set1
  fields as DQS_IN_DLY_1_Set0
0x450 DQS_IN_DLY_1_DBI_Set0
  [4:0] fw_rd_dly_pos_sel_8 — DBI raising edge delay chain control
0x454 DQS_IN_DLY_1_DBI_Set1
  [4:0] fw_rd_dly_pos_sel_8 — DBI raising edge delay chain control
0x458 DQS_IN_DLY_2_Set0
  [8n+4:8n] fw_rd_dly_neg_sel_{n} (n=0..3) — DQS_IN[{n}] falling edge delay chain control
0x45C DQS_IN_DLY_2_Set1
  fields as DQS_IN_DLY_2_Set0
0x460 DQS_IN_DLY_3_Set0
  [8n-28:8n-32] fw_rd_dly_neg_sel_{n} (n=4..7) — DQS_IN[{n}] falling edge delay chain control
0x464 DQS_IN_DLY_3_Set1
  fields as DQS_IN_DLY_3_Set0
0x468 DQS_IN_DLY_3_DBI_Set0
  [4:0] fw_rd_dly_neg_sel_8 — DQS_IN[4] falling edge delay chain control
0x46C DQS_IN_DLY_3_DBI_Set1
  fields as DQS_IN_DLY_3_DBI_Set0
0x470 VALID_WIN_DET_PFIFO_Set0
  [17:9] rx_lag_det_pfifo — Lag flag of pfifo valid window detection in data slice0
  [8:0] rx_lead_det_pfifo — Lead flag of pfifo valid window detection in data slice0
0x474 VALID_WIN_DET_PFIFO_Set1
  fields as VALID_WIN_DET_PFIFO_Set0
0x478 VALID_WIN_DET_NFIFO_Set0
  [17:9] rx_lag_det_nfifo — Lag flag of nfifo valid window detection in data slice0
  [8:0] rx_lead_det_nfifo — Lead flag of nfifo valid window detection in data slice0
0x47C VALID_WIN_DET_NFIFO_Set1
  fields as VALID_WIN_DET_NFIFO_Set0
0x480 DQ_DLY_0_Set0
  [4n+3:4n] dq{n}_dly_sel (n=0..7) — DQ[{n}] delay chain control
0x484 DQ_DLY_0_Set1
  [4n+3:4n] dq{n}_dly_sel (n=0..7) — DQ[{n}] delay chain control
0x488 DQ_DLY_1_Set0
  [11:8] dqs_oe_dly_sel — Slice DQS output enable delay chain control
  [7:4] dm_dly_sel — Slice DM delay chain control
  [3:0] dqs_dly_sel — Slice DQS delay chain control
0x48C DQ_DLY_1_Set1
  fields as DQ_DLY_1_Set0
0x490 CAL_OUT_0_Set0 ro
  [31:0] cal_rd_dly_out — 3-point sampling result from data slice0 ~ 3, selected by cal_rd_dly_out_*
0x494 CAL_OUT_0_Set1 ro
  fields as CAL_OUT_0_Set0
0x498 CAL_OUT_1_Set0 ro
  [31:0] cal_delta_out — 3-point sampling delta width result from data slice0 ~ 3, selected by cal_rd_dly_out_*
0x49C CAL_OUT_1_Set1 ro
  fields as CAL_OUT_1_Set0
0x4A0 WR_FIFO_0_Set0 ro
  [31:0] wr_adr_pos — Write FIFO pointer of raising edge dqs { wr_adr_pos_7[3:0], wr_adr_pos_6[3:0], wr_adr_pos_5[3:0], wr_adr_pos_4[3:0], wr_adr_pos_3[3:0], wr_adr_pos_2[3:0], wr_adr_pos_1[3:0], wr_adr_pos_0[3:0]}
0x4A4 WR_FIFO_0_Set1 ro
  fields as WR_FIFO_0_Set0
0x4A8 WR_FIFO_1_Set0 ro
  [31:0] wr_adr_neg — Write FIFO pointer of falling edge dqs {wr_adr_neg_7[3:0], wr_adr_neg_6[3:0], wr_adr_neg_5[3:0], wr_adr_neg_4[3:0], wr_adr_neg_3[3:0], wr_adr_neg_2[3:0], wr_adr_neg_1[3:0], wr_adr_neg_0[3:0]}
0x4AC WR_FIFO_1_Set1 ro
  fields as WR_FIFO_1_Set0
0x4B0 RD_FIFO_0_Set0 ro
  [31:0] rd_adr_pos — Read FIFO pointer of raising edge dqs {rd_adr_pos_7[3:0], rd_adr_pos_6[3:0], rd_adr_pos_5[3:0], rd_adr_pos_4[3:0], rd_adr_pos_3[3:0], rd_adr_pos_2[3:0], rd_adr_pos_1[3:0], rd_adr_pos_0[3:0]}
0x4B4 RD_FIFO_0_Set1 ro
  fields as RD_FIFO_0_Set0
0x4B8 RD_FIFO_1_Set0 ro
  [31:0] rd_adr_neg — Read FIFO pointer of falling edge dqs {rd_adr_neg_7[3:0], rd_adr_neg_6[3:0], rd_adr_neg_5[3:0], rd_adr_neg_4[3:0], rd_adr_neg_3[3:0], rd_adr_neg_2[3:0], rd_adr_neg_1[3:0], rd_adr_neg_0[3:0]}
0x4BC RD_FIFO_1_Set1 ro
  fields as RD_FIFO_1_Set0
0x4C0 DBI_FIFO_Set0 ro
  [15:0] rw_adr_dbi — {wr_adr_dbi_pos[3:0], wr_adr_dbi_neg[3:0], rd_adr_dbi_pos[3:0], rd_adr_dbi_neg[3:0]}
0x4C4 DBI_FIFO_Set1 ro
  fields as DBI_FIFO_Set0
0x4C8 INT_STATUS_1_Set0
  [31:24] cal_rbdy_int1_neg — interrupt of DQS falling edge hit delay tap right boundary in 3-point calibration
  [23:16] cal_lbdy_int1_neg — interrupt of DQS falling edge hit delay tap left boundary in 3-point calibration
  [15:8] cal_rbdy_int1_pos — interrupt of DQS raising edge hit delay tap right boundary in 3-point calibration
  [7:0] cal_lbdy_int1_pos — interrupt of DQS raising edge hit delay tap left boundary in 3-point calibration
0x4CC INT_STATUS_1_Set1
  fields as INT_STATUS_1_Set0
0x4D0 INT_STATUS_3_Set0
  [21] cal_rbdy_int3_neg — interrupt of DQS falling edge hit delay tap right boundary in DBI 3-point calibration
  [20] cal_lbdy_int3_neg — interrupt of DQS falling edge hit delay tap left boundary in DBI 3-point calibration
  [19] cal_rbdy_int3_pos — interrupt of DQS raising edge hit delay tap right boundary in DBI 3-point calibration
  [18] cal_lbdy_int3_pos — interrupt of DQS raising edge hit delay tap left boundary in DBI 3-point calibration
  [17:9] fifo_ptr_int3_neg — Rx NFIFO pointer error interrupt
  [8:0] fifo_ptr_int3_pos — Rx PFIFO pointer error interrupt
0x4D4 INT_STATUS_3_Set1
  fields as INT_STATUS_3_Set0
0x4D8 PRBS_TMUX4_Set0
  [31] dqs_test — 1: dqs on ,0: dqs off
  [4n+10:4n+8] dq{n}_sel (n=0..5) — 000: force 0 001: force 1 010: PRBS11 011: PRBS11 invert 100: PRBS11 delay one clock cycle 101: from test_pattern register 110: test_pattern invert
0x4DC PRBS_TMUX4_Set1
  fields as PRBS_TMUX4_Set0
0x4E0 PRBS_TMUX5_Set0
  [31] data_prbs11_invs — inverted PRBS11 for data slice
  [26:16] data_prbs11_seed — PRBS11 seed for data slice
  [10:8] dm_sel — 000: force 0 001: force 1 010: PRBS11 011: PRBS11 invert 100: PRBS11 delay one clock cycle 101: from test_pattern register 110: test_pattern invert
  [6:4] dq7_sel — 000: force 0 001: force 1 010: PRBS11 011: PRBS11 invert 100: PRBS11 delay one clock cycle 101: from test_pattern register 110: test_pattern invert
  [2:0] dq6_sel — 000: force 0 001: force 1 010: PRBS11 011: PRBS11 invert 100: PRBS11 delay one clock cycle 101: from test_pattern register 110: test_pattern invert
0x4E4 PRBS_TMUX5_Set1
  fields as PRBS_TMUX5_Set0
0x4E8 RW_EMPH_CTL_Set0
  [29:28] dqs_slewrate — DQS slew rate control pin
  [27:24] dqs_dly_emph — DQS Delay tap control pin
  [13:12] dq_slewrate — DQ/DM slew rate control pin
  [11:8] dq_dly_emph — DQ/DM Delay tap control pin
0x4EC RW_EMPH_CTL_Set1
  fields as RW_EMPH_CTL_Set0
0x4F0 RW_SEL_EMPH_CTL_Set0
  [23:20] dqs_sel_emphn — DQS SEL Emphasis pin
  [19:16] dqs_sel_emphp — DQS SEL Emphasis pin
  [7:4] dq_sel_emphn — DQ/DM SEL Emphasis pin
  [3:0] dq_sel_emphp — DQ/DM SEL Emphasis pin
0x4F4 RW_SEL_EMPH_CTL_Set1
  fields as RW_SEL_EMPH_CTL_Set0
0x4F8 DQ_IO_CTL_0_Set0
  [31:24] dq_oe_sig — FW can config it to control OE of DQ pad 7 : DQ7 of slice : 0 : DQ0 of slice
  [23:16] dq_oe_frc_en — FW can set 1 to control OE of DQ pad 7 : DQ7 of slice : 0 : DQ0 of slice
  [15:8] dq_ie_sig — FW can config it to control IE of DQ pad 7 : DQ7 of slice : 0 : DQ0 of slice
  [7:0] dq_ie_frc_en — FW can set 1 to control IE of DQ pad 7 : DQ7 of slice : 0 : DQ0 of slice
0x4FC DQ_IO_CTL_0_Set1
  fields as DQ_IO_CTL_0_Set0
0x500 DQ_IO_CTL_1_Set0
  [31:24] dq_pat_out — dedicated pattern for DQ out 7 : DQ7 of slice : 0 : DQ0 of slice
  [23] dm_pat_out — dedicated pattern for DM out bit0 : DM of slice
  [3] dm_oe_sig — FW can config it to control OE of DM pad bit0 : DM of slice
  [2] dm_oe_frc_en — array[2]
  [1] dm_ie_sig — FW can config it to control IE of DM pad bit0 : DM of slice
  [0] dm_ie_frc_en — FW can set 1 to control IE of DM pad bit0 : DM of slice
0x504 DQ_IO_CTL_1_Set1
  fields as DQ_IO_CTL_1_Set0
0x508 READ_DBG_CTRL_Set0
  [29:26] dqs_burst_mon_wait_time — Waiting time for monitoring Rx DQS burst length.
  [25:21] rd_dbg_sel1 — Debug selection for data slice
  [20:16] rd_dbg_sel0 — Debug selection for data slice
  [14:12] cal_rd_dly_out_sel — 3-point sampling result selection for data slice 000: dq[1:0] of data slice 001: dq[3:2] of data slice 010: dq[5:4] of data slice 011: dq[7:6] of data slice 100: dq[8] of data slice
  [10] tx_wdata_mask — b1 : Slice TX wdata mask to h00
  [9:8] dqs_dm_pd_en — slice [DQS, DM] PAD power-down b0 : normal, b1: power-down
  [7:0] dq_pd_en — slice DQ[7:0] PAD power-down b0 : normal, b1: power-down
0x50C READ_DBG_CTRL_Set1
  fields as READ_DBG_CTRL_Set0
0x510 MON_Set0 ro
  [30] cal_ftun_under_flg — dqs_en calibration under flow, don't move ftun value. Clear by fw_clr_dqs_int.
  [29] cal_ftun_over_flg — dqs_en calibration over flow, don't move ftun value. Clear by fw_clr_dqs_int.
  [28] cal_ftun_both_hit_flg — dqs_en calibration bot hit eraly and late, don't move ftun value. Clear by fw_clr_dqs_int. This flag only change at dqsen_cal_sel = 0.
  [27:24] fw_tm_dqs_en_ftun — Slice, Internal double buffer value of tm_dqs_en_ftun.
  [21:16] dqs_en_dly_sel_ph — Central sampling point setting of slice0 3-point calibration for DQS enable.
  [7:4] mon_burst_cnt — debug monitor : slice burst_cnt
  [3:0] mon_dqs_cnt — debug monitor : slice dqs_cnt
0x514 MON_Set1 ro
  fields as MON_Set0
0x518 DQ_IO_CTL_2_Set0
  [15:12] dqm_oe_time — [1:0] Control dq/dm oe enable timing. 00: original 01: pre 0.5T enable 10: pre 1T enable 11: pre 1.5T enable [3:2] Control dq/dm oe disable timing. 00: original 01: post 1T disable 11: pre 1T (0.5T if en_crc = 1) disable
  [8:0] data_inv — Invert output value for Tx/Rx DQ/DM 8 : DM of slice 7 : DQ7 of slice : 0 : DQ0 of slice
0x51C DQ_IO_CTL_2_Set1
  fields as DQ_IO_CTL_2_Set0
0x520 READ_CTRL_4_Set0
  [10:5] burst_obvs_num — Control the observed continuous cal_chg_rd_dly signal number before increase Delta value.
  [4] delta_cal_mode — 1: Increase Delta value after observe (burst_obvs_num x256) continuous cal_chg_rd_dly signals with increasing Delta.
  [2] fw_dqsen_ftun_upd — 1: tm_dqs_en_ftun is applicable
  [1] fw_rd_delta_upd — 1: delta_wid_*_sel are applicable
  [0] fw_rd_te_upd — 1: fw_rd_dly_*_sel are applicable
0x524 READ_CTRL_4_Set1
  fields as READ_CTRL_4_Set0
0x5F8 READ_CTRL_0_Set0
  [30:26] dqs_rc_dly_sel — dqs clock to receive_1st delay control
  [23:20] dqs_glitch_dly_ph — Control delay taps to detect DQS glitch.
  [19:16] tm_dq_lat_dly — programmable dq_lat_en_cmd start time 2T DCK unit for 2to1 mode 1T DCK unit for 1to1 mode
  [15:14] dqs_fifo_dly_sel — dqs clock to read FIFO delay control
  [13:8] dqs_en_dly_sel — dqs_en delay chain control
  [6:2] tm_dqs_en — dqs_en latency from read command 2T DCK unit for 2to1 mode 1T DCK unit for 1to1 mode
  [1:0] tm_dqs_en_ftun — dqs_en_ftun latency from read command 0.5T DCK unit
0x5FC READ_CTRL_0_Set1
  fields as READ_CTRL_0_Set0
